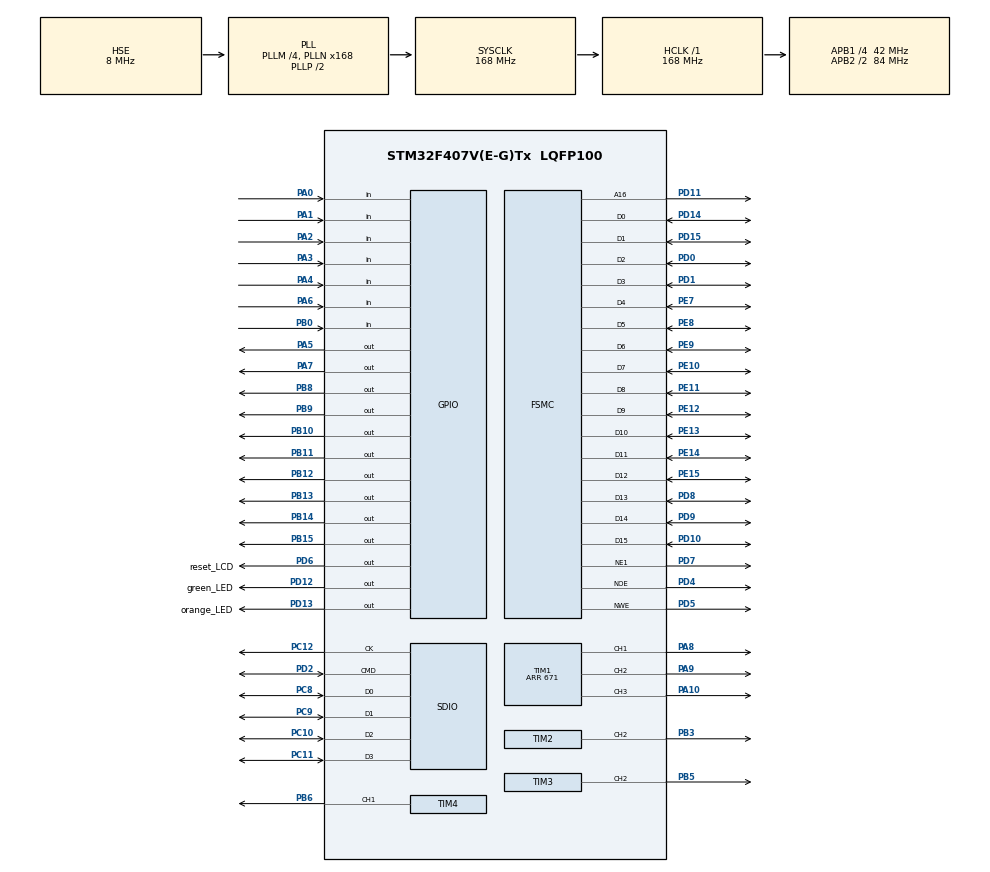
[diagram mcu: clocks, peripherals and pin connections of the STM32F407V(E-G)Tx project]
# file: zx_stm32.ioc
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Dma.MEMTOMEM.0.Direction=DMA_MEMORY_TO_MEMORY
Dma.MEMTOMEM.0.FIFOMode=DMA_FIFOMODE_ENABLE
Dma.MEMTOMEM.0.FIFOThreshold=DMA_FIFO_THRESHOLD_FULL
Dma.MEMTOMEM.0.Instance=DMA2_Stream0
Dma.MEMTOMEM.0.MemBurst=DMA_MBURST_SINGLE
Dma.MEMTOMEM.0.MemDataAlignment=DMA_MDATAALIGN_HALFWORD
Dma.MEMTOMEM.0.MemInc=DMA_MINC_DISABLE
Dma.MEMTOMEM.0.Mode=DMA_NORMAL
Dma.MEMTOMEM.0.PeriphBurst=DMA_PBURST_SINGLE
Dma.MEMTOMEM.0.PeriphDataAlignment=DMA_PDATAALIGN_HALFWORD
Dma.MEMTOMEM.0.PeriphInc=DMA_PINC_DISABLE
Dma.MEMTOMEM.0.Priority=DMA_PRIORITY_HIGH
Dma.MEMTOMEM.1.Direction=DMA_MEMORY_TO_MEMORY
Dma.MEMTOMEM.1.FIFOMode=DMA_FIFOMODE_ENABLE
Dma.MEMTOMEM.1.FIFOThreshold=DMA_FIFO_THRESHOLD_FULL
Dma.MEMTOMEM.1.Instance=DMA2_Stream1
Dma.MEMTOMEM.1.MemBurst=DMA_MBURST_SINGLE
Dma.MEMTOMEM.1.MemDataAlignment=DMA_MDATAALIGN_HALFWORD
Dma.MEMTOMEM.1.MemInc=DMA_MINC_DISABLE
Dma.MEMTOMEM.1.Mode=DMA_NORMAL
Dma.MEMTOMEM.1.PeriphBurst=DMA_PBURST_SINGLE
Dma.MEMTOMEM.1.PeriphDataAlignment=DMA_PDATAALIGN_HALFWORD
Dma.MEMTOMEM.1.PeriphInc=DMA_PINC_ENABLE
Dma.MEMTOMEM.1.Priority=DMA_PRIORITY_HIGH
Dma.Request0=MEMTOMEM
Dma.Request1=MEMTOMEM
Dma.Request2=TIM1_CH3
Dma.TIM1_CH3.2.Direction=DMA_MEMORY_TO_PERIPH
Dma.TIM1_CH3.2.FIFOMode=DMA_FIFOMODE_DISABLE
Dma.TIM1_CH3.2.Instance=DMA2_Stream6
Dma.TIM1_CH3.2.MemDataAlignment=DMA_MDATAALIGN_HALFWORD
Dma.TIM1_CH3.2.MemInc=DMA_MINC_DISABLE
Dma.TIM1_CH3.2.Mode=DMA_CIRCULAR
Dma.TIM1_CH3.2.PeriphDataAlignment=DMA_PDATAALIGN_HALFWORD
Dma.TIM1_CH3.2.PeriphInc=DMA_PINC_DISABLE
Dma.TIM1_CH3.2.Priority=DMA_PRIORITY_LOW
FATFS._CODE_PAGE=1
FATFS._MAX_SS=4096
FSMC.AddressSetupTime1=6
FSMC.BusTurnAroundDuration1=0
FSMC.DataSetupTime1=6
Mcu.Family=STM32F4
Mcu.Name=STM32F407V(E-G)Tx
Mcu.Package=LQFP100
NVIC.DMA2_Stream6_IRQn=true\:0\:0\:false\:false\:true\:false
NVIC.PriorityGroup=NVIC_PRIORITYGROUP_4
NVIC.TIM1_UP_TIM10_IRQn=true\:0\:0\:false\:false\:true\:true
PA0-WKUP.GPIO_PuPd=GPIO_PULLUP
PA0-WKUP.Signal=GPIO_Input
PA1.GPIO_PuPd=GPIO_PULLUP
PA1.Signal=GPIO_Input
PA10.Signal=S_TIM1_CH3
PA2.GPIO_PuPd=GPIO_PULLUP
PA2.Signal=GPIO_Input
PA3.GPIO_PuPd=GPIO_PULLUP
PA3.Signal=GPIO_Input
PA4.GPIO_PuPd=GPIO_PULLUP
PA4.Signal=GPIO_Input
PA5.GPIO_Speed=GPIO_SPEED_FREQ_MEDIUM
PA5.Signal=GPIO_Output
PA6.GPIO_PuPd=GPIO_NOPULL
PA6.Signal=GPIO_Input
PA7.GPIO_Speed=GPIO_SPEED_FREQ_MEDIUM
PA7.Signal=GPIO_Output
PA8.Signal=S_TIM1_CH1
PA9.Signal=S_TIM1_CH2
PB0.Signal=GPIO_Input
PB10.GPIO_ModeDefaultOutputPP=GPIO_MODE_OUTPUT_OD
PB10.GPIO_PuPd=GPIO_PULLUP
PB10.GPIO_Speed=GPIO_SPEED_FREQ_VERY_HIGH
PB10.Signal=GPIO_Output
PB11.GPIO_ModeDefaultOutputPP=GPIO_MODE_OUTPUT_OD
PB11.GPIO_PuPd=GPIO_PULLUP
PB11.GPIO_Speed=GPIO_SPEED_FREQ_VERY_HIGH
PB11.Signal=GPIO_Output
PB12.GPIO_ModeDefaultOutputPP=GPIO_MODE_OUTPUT_OD
PB12.GPIO_PuPd=GPIO_PULLUP
PB12.GPIO_Speed=GPIO_SPEED_FREQ_VERY_HIGH
PB12.Signal=GPIO_Output
PB13.GPIO_ModeDefaultOutputPP=GPIO_MODE_OUTPUT_OD
PB13.GPIO_PuPd=GPIO_PULLUP
PB13.GPIO_Speed=GPIO_SPEED_FREQ_VERY_HIGH
PB13.Signal=GPIO_Output
PB14.GPIO_ModeDefaultOutputPP=GPIO_MODE_OUTPUT_OD
PB14.GPIO_PuPd=GPIO_PULLUP
PB14.GPIO_Speed=GPIO_SPEED_FREQ_VERY_HIGH
PB14.Signal=GPIO_Output
PB15.GPIO_ModeDefaultOutputPP=GPIO_MODE_OUTPUT_OD
PB15.GPIO_PuPd=GPIO_PULLUP
PB15.GPIO_Speed=GPIO_SPEED_FREQ_VERY_HIGH
PB15.Signal=GPIO_Output
PB3.Signal=S_TIM2_CH2
PB5.Signal=S_TIM3_CH2
PB6.Signal=S_TIM4_CH1
PB8.GPIO_ModeDefaultOutputPP=GPIO_MODE_OUTPUT_OD
PB8.GPIO_PuPd=GPIO_PULLUP
PB8.GPIO_Speed=GPIO_SPEED_FREQ_VERY_HIGH
PB8.Signal=GPIO_Output
PB9.GPIO_ModeDefaultOutputPP=GPIO_MODE_OUTPUT_OD
PB9.GPIO_PuPd=GPIO_PULLUP
PB9.GPIO_Speed=GPIO_SPEED_FREQ_VERY_HIGH
PB9.Signal=GPIO_Output
PC10.GPIO_PuPd=GPIO_PULLUP
PC10.Mode=SD_4_bits_Wide_bus
PC10.Signal=SDIO_D2
PC11.GPIO_PuPd=GPIO_PULLUP
PC11.Mode=SD_4_bits_Wide_bus
PC11.Signal=SDIO_D3
PC12.GPIO_PuPd=GPIO_NOPULL
PC12.Mode=SD_4_bits_Wide_bus
PC12.Signal=SDIO_CK
PC8.GPIO_PuPd=GPIO_PULLUP
PC8.Mode=SD_4_bits_Wide_bus
PC8.Signal=SDIO_D0
PC9.GPIO_PuPd=GPIO_PULLUP
PC9.Mode=SD_4_bits_Wide_bus
PC9.Signal=SDIO_D1
PD0.Mode=16b-d1
PD0.Signal=FSMC_D2
PD1.Mode=16b-d1
PD1.Signal=FSMC_D3
PD10.Mode=16b-d1
PD10.Signal=FSMC_D15
PD11.Mode=A16_1
PD11.Signal=FSMC_A16
PD12.GPIO_Label=green_LED
PD12.Signal=GPIO_Output
PD13.GPIO_Label=orange_LED
PD13.Signal=GPIO_Output
PD14.Mode=16b-d1
PD14.Signal=FSMC_D0
PD15.Mode=16b-d1
PD15.Signal=FSMC_D1
PD2.GPIO_PuPd=GPIO_PULLUP
PD2.Mode=SD_4_bits_Wide_bus
PD2.Signal=SDIO_CMD
PD4.Mode=Lcd1
PD4.Signal=FSMC_NOE
PD5.Mode=Lcd1
PD5.Signal=FSMC_NWE
PD6.GPIO_Label=reset_LCD
PD6.Signal=GPIO_Output
PD7.Mode=NorPsramChipSelect1_1
PD7.Signal=FSMC_NE1
PD8.Mode=16b-d1
PD8.Signal=FSMC_D13
PD9.Mode=16b-d1
PD9.Signal=FSMC_D14
PE10.Mode=16b-d1
PE10.Signal=FSMC_D7
PE11.Mode=16b-d1
PE11.Signal=FSMC_D8
PE12.Mode=16b-d1
PE12.Signal=FSMC_D9
PE13.Mode=16b-d1
PE13.Signal=FSMC_D10
PE14.Mode=16b-d1
PE14.Signal=FSMC_D11
PE15.Mode=16b-d1
PE15.Signal=FSMC_D12
PE7.Mode=16b-d1
PE7.Signal=FSMC_D4
PE8.Mode=16b-d1
PE8.Signal=FSMC_D5
PE9.Mode=16b-d1
PE9.Signal=FSMC_D6
PH0-OSC_IN.Mode=HSE-External-Oscillator
PH0-OSC_IN.Signal=RCC_OSC_IN
PH1-OSC_OUT.Mode=HSE-External-Oscillator
PH1-OSC_OUT.Signal=RCC_OSC_OUT
ProjectManager.HeapSize=0x200
ProjectManager.StackSize=0x400
ProjectManager.TargetToolchain=SW4STM32
RCC.48MHZClocksFreq_Value=48000000
RCC.AHBFreq_Value=168000000
RCC.APB1CLKDivider=RCC_HCLK_DIV4
RCC.APB1Freq_Value=42000000
RCC.APB1TimFreq_Value=84000000
RCC.APB2CLKDivider=RCC_HCLK_DIV2
RCC.APB2Freq_Value=84000000
RCC.APB2TimFreq_Value=168000000
RCC.CortexFreq_Value=168000000
RCC.HCLKFreq_Value=168000000
RCC.HSE_VALUE=8000000
RCC.HSI_VALUE=16000000
RCC.LSE_VALUE=32768
RCC.PLLM=4
RCC.PLLN=168
RCC.PLLQ=7
RCC.PLLSourceVirtual=RCC_PLLSOURCE_HSE
RCC.SYSCLKFreq_VALUE=168000000
RCC.SYSCLKSource=RCC_SYSCLKSOURCE_PLLCLK
RCC.VCOOutputFreq_Value=336000000
SH.S_TIM1_CH1.0=TIM1_CH1,Output Compare1 CH1
SH.S_TIM1_CH2.0=TIM1_CH2,Output Compare2 CH2
SH.S_TIM1_CH3.0=TIM1_CH3,Output Compare3 CH3
SH.S_TIM2_CH2.0=TIM2_CH2,PWM Generation2 CH2
SH.S_TIM3_CH2.0=TIM3_CH2,PWM Generation2 CH2
SH.S_TIM4_CH1.0=TIM4_CH1,PWM Generation1 CH1
TIM1.Channel-Output\ Compare1\ CH1=TIM_CHANNEL_1
TIM1.Channel-Output\ Compare2\ CH2=TIM_CHANNEL_2
TIM1.Channel-Output\ Compare3\ CH3=TIM_CHANNEL_3
TIM1.OCMode_3=TIM_OCMODE_TIMING
TIM1.Period=671
TIM1.Pulse-Output\ Compare1\ CH1=335
TIM1.Pulse-Output\ Compare2\ CH2=335
TIM1.Pulse-Output\ Compare3\ CH3=335
TIM10.Period=0xffff
TIM10.Prescaler=47
TIM11.Period=383
TIM11.Prescaler=0
TIM2.Channel-PWM\ Generation2\ CH2=TIM_CHANNEL_2
TIM2.ClockDivision=TIM_CLOCKDIVISION_DIV1
TIM2.Period=671
TIM2.Pulse-PWM\ Generation2\ CH2=335
TIM3.Channel-PWM\ Generation2\ CH2=TIM_CHANNEL_2
TIM3.Period=671
TIM3.Pulse-PWM\ Generation2\ CH2=335
TIM4.Channel-PWM\ Generation1\ CH1=TIM_CHANNEL_1
TIM4.Period=671
TIM4.Pulse-PWM\ Generation1\ CH1=335
VP_FATFS_VS_SDIO.Mode=SDIO
VP_RNG_VS_RNG.Mode=RNG_Activate
VP_TIM10_VS_ClockSourceINT.Mode=Enable_Timer
VP_TIM11_VS_ClockSourceINT.Mode=Enable_Timer
VP_TIM1_VS_ClockSourceINT.Mode=Internal
VP_TIM2_VS_ClockSourceINT.Mode=Internal
VP_TIM3_VS_ClockSourceINT.Mode=Internal
VP_TIM4_VS_ClockSourceINT.Mode=Internal
board=zx_stm32

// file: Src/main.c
/**
  ******************************************************************************
  * File Name          : main.c
  * Description        : Main program body
  ******************************************************************************
  * This notice applies to any and all portions of this file
  * that are not between comment pairs USER CODE BEGIN and
  * USER CODE END. Other portions of this file, whether
  * inserted by the user or by software development tools
  * are owned by their respective copyright owners.
  *
  * Copyright (c) 2018 STMicroelectronics International N.V.
  * All rights reserved.
  *
  * Redistribution and use in source and binary forms, with or without
  * modification, are permitted, provided that the following conditions are met:
  *
  * 1. Redistribution of source code must retain the above copyright notice,
  *    this list of conditions and the following disclaimer.
  * 2. Redistributions in binary form must reproduce the above copyright notice,
  *    this list of conditions and the following disclaimer in the documentation
  *    and/or other materials provided with the distribution.
  * 3. Neither the name of STMicroelectronics nor the names of other
  *    contributors to this software may be used to endorse or promote products
  *    derived from this software without specific written permission.
  * 4. This software, including modifications and/or derivative works of this
  *    software, must execute solely and exclusively on microcontroller or
  *    microprocessor devices manufactured by or for STMicroelectronics.
  * 5. Redistribution and use of this software other than as permitted under
  *    this license is void and will automatically terminate your rights under
  *    this license.
  *
  * THIS SOFTWARE IS PROVIDED BY STMICROELECTRONICS AND CONTRIBUTORS "AS IS"
  * AND ANY EXPRESS, IMPLIED OR STATUTORY WARRANTIES, INCLUDING, BUT NOT
  * LIMITED TO, THE IMPLIED WARRANTIES OF MERCHANTABILITY, FITNESS FOR A
  * PARTICULAR PURPOSE AND NON-INFRINGEMENT OF THIRD PARTY INTELLECTUAL PROPERTY
  * RIGHTS ARE DISCLAIMED TO THE FULLEST EXTENT PERMITTED BY LAW. IN NO EVENT
  * SHALL STMICROELECTRONICS OR CONTRIBUTORS BE LIABLE FOR ANY DIRECT, INDIRECT,
  * INCIDENTAL, SPECIAL, EXEMPLARY, OR CONSEQUENTIAL DAMAGES (INCLUDING, BUT NOT
  * LIMITED TO, PROCUREMENT OF SUBSTITUTE GOODS OR SERVICES; LOSS OF USE, DATA,
  * OR PROFITS; OR BUSINESS INTERRUPTION) HOWEVER CAUSED AND ON ANY THEORY OF
  * LIABILITY, WHETHER IN CONTRACT, STRICT LIABILITY, OR TORT (INCLUDING
  * NEGLIGENCE OR OTHERWISE) ARISING IN ANY WAY OUT OF THE USE OF THIS SOFTWARE,
  * EVEN IF ADVISED OF THE POSSIBILITY OF SUCH DAMAGE.
  *
  ******************************************************************************
  */

#include "main.h"
#include "stm32f4xx_hal.h"
#include "dma.h"
#include "fatfs.h"
#include "rng.h"
#include "sdio.h"
#include "tim.h"
#include "gpio.h"
#include "fsmc.h"

/* USER CODE BEGIN Includes */
#include "zx.h"

/* USER CODE END Includes */

/* USER CODE BEGIN PV */
/* Private variables ---------------------------------------------------------*/

/* USER CODE END PV */

void SystemClock_Config(void);

/* USER CODE BEGIN PFP */
/* Private function prototypes -----------------------------------------------*/
/* USER CODE END PFP */

int main(void)
{

  /* MCU Configuration----------------------------------------------------------*/

  /* Reset of all peripherals, Initializes the Flash interface and the Systick. */
  HAL_Init();

  /* Configure the system clock */
  SystemClock_Config();

  /* Initialize all configured peripherals */
  MX_GPIO_Init();
  MX_DMA_Init();
  MX_FSMC_Init();
  MX_TIM10_Init();
  MX_SDIO_SD_Init();
  MX_FATFS_Init();
  MX_TIM11_Init();
  MX_TIM2_Init();
  MX_TIM3_Init();
  MX_TIM4_Init();
  MX_TIM1_Init();
  MX_RNG_Init();

  /* Infinite loop */
  /* USER CODE BEGIN WHILE */

  while (1)
  {
	  zx_run();

  /* USER CODE END WHILE */

  }

}

/** System Clock Configuration
*/
void SystemClock_Config(void)
{

  RCC_OscInitTypeDef RCC_OscInitStruct;
  RCC_ClkInitTypeDef RCC_ClkInitStruct;

    /**Configure the main internal regulator output voltage
    */
  __HAL_RCC_PWR_CLK_ENABLE();

  __HAL_PWR_VOLTAGESCALING_CONFIG(PWR_REGULATOR_VOLTAGE_SCALE1);

    /**Initializes the CPU, AHB and APB busses clocks
    */
  RCC_OscInitStruct.OscillatorType = RCC_OSCILLATORTYPE_HSE;
  RCC_OscInitStruct.HSEState = RCC_HSE_ON;
  RCC_OscInitStruct.PLL.PLLState = RCC_PLL_ON;
  RCC_OscInitStruct.PLL.PLLSource = RCC_PLLSOURCE_HSE;
  RCC_OscInitStruct.PLL.PLLM = 4;
  RCC_OscInitStruct.PLL.PLLN = 168;
  RCC_OscInitStruct.PLL.PLLP = RCC_PLLP_DIV2;
  RCC_OscInitStruct.PLL.PLLQ = 7;
  if (HAL_RCC_OscConfig(&RCC_OscInitStruct) != HAL_OK)
  {
    _Error_Handler(__FILE__, __LINE__);
  }

    /**Initializes the CPU, AHB and APB busses clocks
    */
  RCC_ClkInitStruct.ClockType = RCC_CLOCKTYPE_HCLK|RCC_CLOCKTYPE_SYSCLK
                              |RCC_CLOCKTYPE_PCLK1|RCC_CLOCKTYPE_PCLK2;
  RCC_ClkInitStruct.SYSCLKSource = RCC_SYSCLKSOURCE_PLLCLK;
  RCC_ClkInitStruct.AHBCLKDivider = RCC_SYSCLK_DIV1;
  RCC_ClkInitStruct.APB1CLKDivider = RCC_HCLK_DIV4;
  RCC_ClkInitStruct.APB2CLKDivider = RCC_HCLK_DIV2;

  if (HAL_RCC_ClockConfig(&RCC_ClkInitStruct, FLASH_LATENCY_5) != HAL_OK)
  {
    _Error_Handler(__FILE__, __LINE__);
  }

    /**Configure the Systick interrupt time
    */
  HAL_SYSTICK_Config(HAL_RCC_GetHCLKFreq()/1000);

    /**Configure the Systick
    */
  HAL_SYSTICK_CLKSourceConfig(SYSTICK_CLKSOURCE_HCLK);

  /* SysTick_IRQn interrupt configuration */
  HAL_NVIC_SetPriority(SysTick_IRQn, 0, 0);
}

void _Error_Handler(char * file, int line)
{
  while(1)
  {
  }
}

/************************ (C) COPYRIGHT STMicroelectronics *****END OF FILE****/
